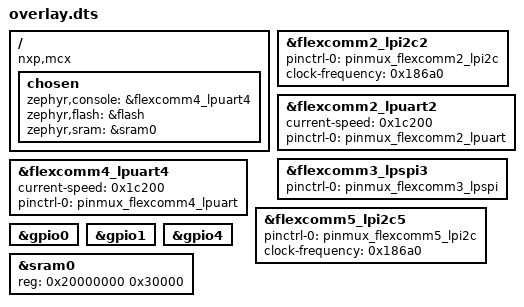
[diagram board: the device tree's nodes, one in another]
/ {
	compatible = "nxp,mcx", "nxp,mcxn236";
	chosen {
		zephyr,console = &flexcomm4_lpuart4;
		zephyr,flash = &flash;
		zephyr,sram = &sram0;
	};
};
&flexcomm2_lpi2c2{
	status = "okay";
	pinctrl-0 = < &pinmux_flexcomm2_lpi2c >;
	pinctrl-names = "default";
	clock-frequency = < 0x186a0 >;
};
&flexcomm2_lpuart2{
	status = "okay";
	current-speed = < 0x1c200 >;
	pinctrl-0 = < &pinmux_flexcomm2_lpuart >;
	pinctrl-names = "default";
};
&flexcomm3_lpspi3{
	status = "okay";
	pinctrl-0 = < &pinmux_flexcomm3_lpspi >;
	pinctrl-names = "default";
};
&flexcomm4_lpuart4{
	status = "okay";
	current-speed = < 0x1c200 >;
	pinctrl-0 = < &pinmux_flexcomm4_lpuart >;
	pinctrl-names = "default";
};
&flexcomm5_lpi2c5{
	status = "okay";
	pinctrl-0 = < &pinmux_flexcomm5_lpi2c >;
	pinctrl-names = "default";
	clock-frequency = < 0x186a0 >;
};
&gpio0{
	status = "okay";
};
&gpio1{
	status = "okay";
};
&gpio4{
	status = "okay";
};
&sram0{
	reg = < 0x20000000 0x30000 >;
};
